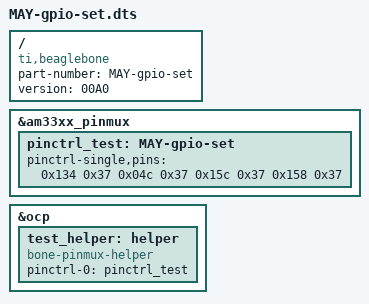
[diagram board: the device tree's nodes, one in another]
/*  
* Copyright (C) 2012 Texas Instruments Incorporated - http://www.ti.com/
*
* This program is free software; you can redistribute it and/or modify
* it under the terms of the GNU General Purpose License Version 2 as
* published by the Free Software Foundation
*
* Original from: github.com/jadonk/validation-scripts/blob/master/test-capemgr/ 
*
* Modified by Derek Molloy for the example on www.derekmolloy.ie
* that maps GPIO pins for the example
*/

/dts-v1/;
/plugin/;

/{
       compatible = "ti,beaglebone", "ti,beaglebone-black";
       part-number = "MAY-gpio-set";
       version = "00A0";

       fragment@0 {
             target = <&am33xx_pinmux>;
            
             __overlay__ {
                  pinctrl_test: MAY-gpio-set {
			pinctrl-single,pins = <

			    0x134 0x37  // P9_15  48 INPUT  MODE7 pullup
			    0x04c 0x37  // P9_16  51 INPUT  MODE7 pullup
			    0x15c 0x37  // P9_17   5 INPUT  MODE7 pullup
			    0x158 0x37  // P9_18   4 INPUT  MODE7 pullup
                       
                    /* OUTPUT  GPIO(mode7) 0x07 pulldown, 0x17 pullup, 0x?f no pullup/down */
			        /* INPUT   GPIO(mode7) 0x27 pulldown, 0x37 pullup, 0x?f no pullup/down */

			>;
		  };
             };
       };

       fragment@1 {
		target = <&ocp>;
		__overlay__ {
			test_helper: helper {
				compatible = "bone-pinmux-helper";
				pinctrl-names = "default";
				pinctrl-0 = <&pinctrl_test>;
				status = "okay";
			};
		};
	};
};
